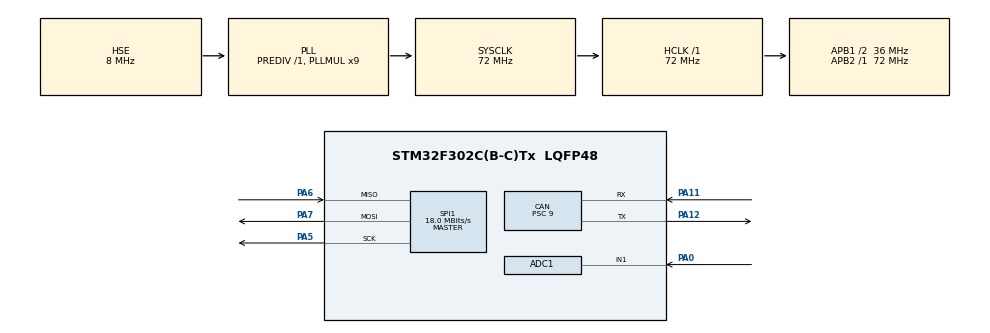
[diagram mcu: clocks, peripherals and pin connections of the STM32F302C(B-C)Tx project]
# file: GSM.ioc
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ADC1.Channel-0\#ChannelRegularConversion=ADC_CHANNEL_1
ADC1.NbrOfConversionFlag=1
ADC1.Offset-0\#ChannelRegularConversion=0
ADC1.OffsetNumber-0\#ChannelRegularConversion=ADC_OFFSET_NONE
ADC1.Rank-0\#ChannelRegularConversion=1
ADC1.SamplingTime-0\#ChannelRegularConversion=ADC_SAMPLETIME_1CYCLE_5
ADC1.SubFamily=STM32F302xC
ADC1.master=1
CAN.ABOM=ENABLE
CAN.BS1=CAN_BS1_6TQ
CAN.CalculateBaudRate=500000
CAN.CalculateTimeBit=2000
CAN.CalculateTimeQuantum=250.0
CAN.NART=ENABLE
CAN.Prescaler=9
CAN.RFLM=ENABLE
CAN.SJW=CAN_SJW_4TQ
FREERTOS.INCLUDE_uxTaskGetStackHighWaterMark=1
FREERTOS.INCLUDE_vTaskDelayUntil=1
FREERTOS.MEMORY_ALLOCATION=1
FREERTOS.Tasks01=Task100Hz,24,512,RunTask100Hz,Default,NULL,Static,Task100HzBuffer,Task100HzControlBlock;Task1Hz,24,512,RunTask1Hz,Default,NULL,Static,Task1HzBuffer,Task1HzControlBlock;Task1kHz,8,512,RunTask1kHz,Default,NULL,Static,Task1kHzBuffer,Task1kHzControlBlock;TaskCanRx,24,512,RunTaskCanRx,Default,NULL,Static,TaskCanRxBuffer,TaskCanRxControlBlock;TaskCanTx,24,512,RunTaskCanTx,Default,NULL,Static,TaskCanTxBuffer,TaskCanTxControlBlock
FREERTOS.configCHECK_FOR_STACK_OVERFLOW=2
FREERTOS.configUSE_NEWLIB_REENTRANT=1
FREERTOS.configUSE_TICK_HOOK=1
FREERTOS.configUSE_TRACE_FACILITY=1
IWDG.Reload=LSI_FREQUENCY / IWDG_PRESCALER / IWDG_RESET_FREQUENCY
IWDG.Window=IWDG_WINDOW_DISABLE_VALUE
Mcu.Family=STM32F3
Mcu.Name=STM32F302C(B-C)Tx
Mcu.Package=LQFP48
Mcu.UserConstants=IWDG_WINDOW_DISABLE_VALUE,4095;IWDG_PRESCALER,4;IWDG_RESET_FREQUENCY,5;LSI_FREQUENCY,40000;TASK_STACK_SIZE,512
NVIC.CAN_RX1_IRQn=true\:5\:0\:false\:false\:true\:true\:true\:true\:true
NVIC.PriorityGroup=NVIC_PRIORITYGROUP_4
NVIC.TIM1_UP_TIM16_IRQn=true\:0\:0\:false\:false\:true\:false\:false\:true\:true
NVIC.TimeBase=TIM1_UP_TIM16_IRQn
NVIC.TimeBaseIP=TIM1
NVIC.USB_HP_CAN_TX_IRQn=true\:5\:0\:false\:false\:true\:true\:true\:true\:true
NVIC.USB_LP_CAN_RX0_IRQn=true\:5\:0\:false\:false\:true\:true\:true\:true\:true
PA0.Mode=IN1-Single-Ended
PA0.Signal=ADC1_IN1
PA11.Mode=CAN_Activate
PA11.Signal=CAN_RX
PA12.Mode=CAN_Activate
PA12.Signal=CAN_TX
PA13.Mode=Trace_Asynchronous_SW
PA13.Signal=SYS_JTMS-SWDIO
PA14.Mode=Trace_Asynchronous_SW
PA14.Signal=SYS_JTCK-SWCLK
PA5.Mode=Full_Duplex_Master
PA5.Signal=SPI1_SCK
PA6.Mode=Full_Duplex_Master
PA6.Signal=SPI1_MISO
PA7.Mode=Full_Duplex_Master
PA7.Signal=SPI1_MOSI
PB3.Mode=Trace_Asynchronous_SW
PB3.Signal=SYS_JTDO-TRACESWO
PF0-OSC_IN.Mode=HSE-External-Oscillator
PF0-OSC_IN.Signal=RCC_OSC_IN
PF1-OSC_OUT.Mode=HSE-External-Oscillator
PF1-OSC_OUT.Signal=RCC_OSC_OUT
ProjectManager.HeapSize=0x0
ProjectManager.StackSize=0x400
ProjectManager.TargetToolchain=STM32CubeIDE
RCC.AHBFreq_Value=72000000
RCC.APB1CLKDivider=RCC_HCLK_DIV2
RCC.APB1Freq_Value=36000000
RCC.APB1TimFreq_Value=72000000
RCC.APB2Freq_Value=72000000
RCC.APB2TimFreq_Value=72000000
RCC.CortexFreq_Value=72000000
RCC.HCLKFreq_Value=72000000
RCC.HSE_VALUE=8000000
RCC.HSI_VALUE=8000000
RCC.LSE_VALUE=32768
RCC.PLLMUL=RCC_PLL_MUL9
RCC.PLLSourceVirtual=RCC_PLLSOURCE_HSE
RCC.SYSCLKFreq_VALUE=72000000
RCC.SYSCLKSourceVirtual=RCC_SYSCLKSOURCE_PLLCLK
RCC.USBFreq_Value=72000000
SPI1.BaudRatePrescaler=SPI_BAUDRATEPRESCALER_4
SPI1.CalculateBaudRate=18.0 MBits/s
SPI1.Direction=SPI_DIRECTION_2LINES
SPI1.Mode=SPI_MODE_MASTER
SPI1.VirtualType=VM_MASTER
VP_FREERTOS_VS_CMSIS_V2.Mode=CMSIS_V2
VP_IWDG_VS_IWDG.Mode=IWDG_Activate
VP_SYS_VS_tim1.Mode=TIM1
board=custom

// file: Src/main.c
/* USER CODE BEGIN Header */
/**
 ******************************************************************************
 * @file           : main.c
 * @brief          : Main program body
 ******************************************************************************
 * @attention
 *
 * <h2><center>&copy; Copyright (c) 2023 STMicroelectronics.
 * All rights reserved.</center></h2>
 *
 * This software component is licensed by ST under Ultimate Liberty license
 * SLA0044, the "License"; You may not use this file except in compliance with
 * the License. You may obtain a copy of the License at:
 *                             www.st.com/SLA0044
 *
 ******************************************************************************
 */
/* USER CODE END Header */
#include "main.h"
#include "cmsis_os.h"

typedef StaticTask_t osStaticThreadDef_t;

ADC_HandleTypeDef hadc1;

CAN_HandleTypeDef hcan;

IWDG_HandleTypeDef hiwdg;

SPI_HandleTypeDef hspi1;

/* Definitions for Task100Hz */
osThreadId_t         Task100HzHandle;
uint32_t             Task100HzBuffer[512];
osStaticThreadDef_t  Task100HzControlBlock;
const osThreadAttr_t Task100Hz_attributes = {
    .name       = "Task100Hz",
    .cb_mem     = &Task100HzControlBlock,
    .cb_size    = sizeof(Task100HzControlBlock),
    .stack_mem  = &Task100HzBuffer[0],
    .stack_size = sizeof(Task100HzBuffer),
    .priority   = (osPriority_t)osPriorityNormal,
};
/* Definitions for Task1Hz */
osThreadId_t         Task1HzHandle;
uint32_t             Task1HzBuffer[512];
osStaticThreadDef_t  Task1HzControlBlock;
const osThreadAttr_t Task1Hz_attributes = {
    .name       = "Task1Hz",
    .cb_mem     = &Task1HzControlBlock,
    .cb_size    = sizeof(Task1HzControlBlock),
    .stack_mem  = &Task1HzBuffer[0],
    .stack_size = sizeof(Task1HzBuffer),
    .priority   = (osPriority_t)osPriorityNormal,
};
/* Definitions for Task1kHz */
osThreadId_t         Task1kHzHandle;
uint32_t             Task1kHzBuffer[512];
osStaticThreadDef_t  Task1kHzControlBlock;
const osThreadAttr_t Task1kHz_attributes = {
    .name       = "Task1kHz",
    .cb_mem     = &Task1kHzControlBlock,
    .cb_size    = sizeof(Task1kHzControlBlock),
    .stack_mem  = &Task1kHzBuffer[0],
    .stack_size = sizeof(Task1kHzBuffer),
    .priority   = (osPriority_t)osPriorityLow,
};
/* Definitions for TaskCanRx */
osThreadId_t         TaskCanRxHandle;
uint32_t             TaskCanRxBuffer[512];
osStaticThreadDef_t  TaskCanRxControlBlock;
const osThreadAttr_t TaskCanRx_attributes = {
    .name       = "TaskCanRx",
    .cb_mem     = &TaskCanRxControlBlock,
    .cb_size    = sizeof(TaskCanRxControlBlock),
    .stack_mem  = &TaskCanRxBuffer[0],
    .stack_size = sizeof(TaskCanRxBuffer),
    .priority   = (osPriority_t)osPriorityNormal,
};
/* Definitions for TaskCanTx */
osThreadId_t         TaskCanTxHandle;
uint32_t             TaskCanTxBuffer[512];
osStaticThreadDef_t  TaskCanTxControlBlock;
const osThreadAttr_t TaskCanTx_attributes = {
    .name       = "TaskCanTx",
    .cb_mem     = &TaskCanTxControlBlock,
    .cb_size    = sizeof(TaskCanTxControlBlock),
    .stack_mem  = &TaskCanTxBuffer[0],
    .stack_size = sizeof(TaskCanTxBuffer),
    .priority   = (osPriority_t)osPriorityNormal,
};

void        SystemClock_Config(void);
static void MX_GPIO_Init(void);
static void MX_CAN_Init(void);
static void MX_ADC1_Init(void);
static void MX_SPI1_Init(void);
static void MX_IWDG_Init(void);
void        RunTask100Hz(void *argument);
void        RunTask1Hz(void *argument);
void        RunTask1kHz(void *argument);
void        RunTaskCanRx(void *argument);
void        RunTaskCanTx(void *argument);

int main(void)
{

    /* MCU Configuration--------------------------------------------------------*/

    /* Reset of all peripherals, Initializes the Flash interface and the Systick. */
    HAL_Init();

    /* Configure the system clock */
    SystemClock_Config();

    /* Initialize all configured peripherals */
    MX_GPIO_Init();
    MX_CAN_Init();
    MX_ADC1_Init();
    MX_SPI1_Init();
    MX_IWDG_Init();

    /* Init scheduler */
    osKernelInitialize();

    /* Create the thread(s) */
    /* creation of Task100Hz */
    Task100HzHandle = osThreadNew(RunTask100Hz, NULL, &Task100Hz_attributes);

    /* creation of Task1Hz */
    Task1HzHandle = osThreadNew(RunTask1Hz, NULL, &Task1Hz_attributes);

    /* creation of Task1kHz */
    Task1kHzHandle = osThreadNew(RunTask1kHz, NULL, &Task1kHz_attributes);

    /* creation of TaskCanRx */
    TaskCanRxHandle = osThreadNew(RunTaskCanRx, NULL, &TaskCanRx_attributes);

    /* creation of TaskCanTx */
    TaskCanTxHandle = osThreadNew(RunTaskCanTx, NULL, &TaskCanTx_attributes);

    /* Start scheduler */
    osKernelStart();

    /* We should never get here as control is now taken by the scheduler */
    /* Infinite loop */
    while (1)
    {

    }
}

void SystemClock_Config(void)
{
    RCC_OscInitTypeDef       RCC_OscInitStruct = { 0 };
    RCC_ClkInitTypeDef       RCC_ClkInitStruct = { 0 };
    RCC_PeriphCLKInitTypeDef PeriphClkInit     = { 0 };

    /** Initializes the RCC Oscillators according to the specified parameters
     * in the RCC_OscInitTypeDef structure.
     */
    RCC_OscInitStruct.OscillatorType = RCC_OSCILLATORTYPE_LSI | RCC_OSCILLATORTYPE_HSE;
    RCC_OscInitStruct.HSEState       = RCC_HSE_ON;
    RCC_OscInitStruct.HSEPredivValue = RCC_HSE_PREDIV_DIV1;
    RCC_OscInitStruct.HSIState       = RCC_HSI_ON;
    RCC_OscInitStruct.LSIState       = RCC_LSI_ON;
    RCC_OscInitStruct.PLL.PLLState   = RCC_PLL_ON;
    RCC_OscInitStruct.PLL.PLLSource  = RCC_PLLSOURCE_HSE;
    RCC_OscInitStruct.PLL.PLLMUL     = RCC_PLL_MUL9;
    if (HAL_RCC_OscConfig(&RCC_OscInitStruct) != HAL_OK)
    {
        Error_Handler();
    }

    /** Initializes the CPU, AHB and APB buses clocks
     */
    RCC_ClkInitStruct.ClockType = RCC_CLOCKTYPE_HCLK | RCC_CLOCKTYPE_SYSCLK | RCC_CLOCKTYPE_PCLK1 | RCC_CLOCKTYPE_PCLK2;
    RCC_ClkInitStruct.SYSCLKSource   = RCC_SYSCLKSOURCE_PLLCLK;
    RCC_ClkInitStruct.AHBCLKDivider  = RCC_SYSCLK_DIV1;
    RCC_ClkInitStruct.APB1CLKDivider = RCC_HCLK_DIV2;
    RCC_ClkInitStruct.APB2CLKDivider = RCC_HCLK_DIV1;

    if (HAL_RCC_ClockConfig(&RCC_ClkInitStruct, FLASH_LATENCY_2) != HAL_OK)
    {
        Error_Handler();
    }
    PeriphClkInit.PeriphClockSelection = RCC_PERIPHCLK_ADC12;
    PeriphClkInit.Adc12ClockSelection  = RCC_ADC12PLLCLK_DIV1;
    if (HAL_RCCEx_PeriphCLKConfig(&PeriphClkInit) != HAL_OK)
    {
        Error_Handler();
    }
}

static void MX_ADC1_Init(void)
{

    ADC_MultiModeTypeDef   multimode = { 0 };
    ADC_ChannelConfTypeDef sConfig   = { 0 };

    /** Common config
     */
    hadc1.Instance                   = ADC1;
    hadc1.Init.ClockPrescaler        = ADC_CLOCK_ASYNC_DIV1;
    hadc1.Init.Resolution            = ADC_RESOLUTION_12B;
    hadc1.Init.ScanConvMode          = ADC_SCAN_DISABLE;
    hadc1.Init.ContinuousConvMode    = DISABLE;
    hadc1.Init.DiscontinuousConvMode = DISABLE;
    hadc1.Init.ExternalTrigConvEdge  = ADC_EXTERNALTRIGCONVEDGE_NONE;
    hadc1.Init.ExternalTrigConv      = ADC_SOFTWARE_START;
    hadc1.Init.DataAlign             = ADC_DATAALIGN_RIGHT;
    hadc1.Init.NbrOfConversion       = 1;
    hadc1.Init.DMAContinuousRequests = DISABLE;
    hadc1.Init.EOCSelection          = ADC_EOC_SINGLE_CONV;
    hadc1.Init.LowPowerAutoWait      = DISABLE;
    hadc1.Init.Overrun               = ADC_OVR_DATA_OVERWRITTEN;
    if (HAL_ADC_Init(&hadc1) != HAL_OK)
    {
        Error_Handler();
    }

    /** Configure the ADC multi-mode
     */
    multimode.Mode = ADC_MODE_INDEPENDENT;
    if (HAL_ADCEx_MultiModeConfigChannel(&hadc1, &multimode) != HAL_OK)
    {
        Error_Handler();
    }

    /** Configure Regular Channel
     */
    sConfig.Channel      = ADC_CHANNEL_1;
    sConfig.Rank         = ADC_REGULAR_RANK_1;
    sConfig.SingleDiff   = ADC_SINGLE_ENDED;
    sConfig.SamplingTime = ADC_SAMPLETIME_1CYCLE_5;
    sConfig.OffsetNumber = ADC_OFFSET_NONE;
    sConfig.Offset       = 0;
    if (HAL_ADC_ConfigChannel(&hadc1, &sConfig) != HAL_OK)
    {
        Error_Handler();
    }
}

static void MX_CAN_Init(void)
{

    hcan.Instance                  = CAN;
    hcan.Init.Prescaler            = 9;
    hcan.Init.Mode                 = CAN_MODE_NORMAL;
    hcan.Init.SyncJumpWidth        = CAN_SJW_4TQ;
    hcan.Init.TimeSeg1             = CAN_BS1_6TQ;
    hcan.Init.TimeSeg2             = CAN_BS2_1TQ;
    hcan.Init.TimeTriggeredMode    = DISABLE;
    hcan.Init.AutoBusOff           = ENABLE;
    hcan.Init.AutoWakeUp           = DISABLE;
    hcan.Init.AutoRetransmission   = ENABLE;
    hcan.Init.ReceiveFifoLocked    = ENABLE;
    hcan.Init.TransmitFifoPriority = DISABLE;
    if (HAL_CAN_Init(&hcan) != HAL_OK)
    {
        Error_Handler();
    }
}

static void MX_IWDG_Init(void)
{

    hiwdg.Instance       = IWDG;
    hiwdg.Init.Prescaler = IWDG_PRESCALER_4;
    hiwdg.Init.Window    = IWDG_WINDOW_DISABLE_VALUE;
    hiwdg.Init.Reload    = LSI_FREQUENCY / IWDG_PRESCALER / IWDG_RESET_FREQUENCY;
    if (HAL_IWDG_Init(&hiwdg) != HAL_OK)
    {
        Error_Handler();
    }
}

static void MX_SPI1_Init(void)
{

    /* SPI1 parameter configuration*/
    hspi1.Instance               = SPI1;
    hspi1.Init.Mode              = SPI_MODE_MASTER;
    hspi1.Init.Direction         = SPI_DIRECTION_2LINES;
    hspi1.Init.DataSize          = SPI_DATASIZE_4BIT;
    hspi1.Init.CLKPolarity       = SPI_POLARITY_LOW;
    hspi1.Init.CLKPhase          = SPI_PHASE_1EDGE;
    hspi1.Init.NSS               = SPI_NSS_SOFT;
    hspi1.Init.BaudRatePrescaler = SPI_BAUDRATEPRESCALER_4;
    hspi1.Init.FirstBit          = SPI_FIRSTBIT_MSB;
    hspi1.Init.TIMode            = SPI_TIMODE_DISABLE;
    hspi1.Init.CRCCalculation    = SPI_CRCCALCULATION_DISABLE;
    hspi1.Init.CRCPolynomial     = 7;
    hspi1.Init.CRCLength         = SPI_CRC_LENGTH_DATASIZE;
    hspi1.Init.NSSPMode          = SPI_NSS_PULSE_ENABLE;
    if (HAL_SPI_Init(&hspi1) != HAL_OK)
    {
        Error_Handler();
    }
}

static void MX_GPIO_Init(void)
{
    GPIO_InitTypeDef GPIO_InitStruct = { 0 };

    /* GPIO Ports Clock Enable */
    __HAL_RCC_GPIOC_CLK_ENABLE();
    __HAL_RCC_GPIOF_CLK_ENABLE();
    __HAL_RCC_GPIOA_CLK_ENABLE();
    __HAL_RCC_GPIOB_CLK_ENABLE();

    /*Configure GPIO pins : PC13 PC14 PC15 */
    GPIO_InitStruct.Pin  = GPIO_PIN_13 | GPIO_PIN_14 | GPIO_PIN_15;
    GPIO_InitStruct.Mode = GPIO_MODE_ANALOG;
    GPIO_InitStruct.Pull = GPIO_NOPULL;
    HAL_GPIO_Init(GPIOC, &GPIO_InitStruct);

    /*Configure GPIO pins : PA1 PA2 PA3 PA4
                             PA8 PA9 PA10 PA15 */
    GPIO_InitStruct.Pin =
        GPIO_PIN_1 | GPIO_PIN_2 | GPIO_PIN_3 | GPIO_PIN_4 | GPIO_PIN_8 | GPIO_PIN_9 | GPIO_PIN_10 | GPIO_PIN_15;
    GPIO_InitStruct.Mode = GPIO_MODE_ANALOG;
    GPIO_InitStruct.Pull = GPIO_NOPULL;
    HAL_GPIO_Init(GPIOA, &GPIO_InitStruct);

    /*Configure GPIO pins : PB0 PB1 PB2 PB10
                             PB11 PB12 PB13 PB14
                             PB15 PB4 PB5 PB6
                             PB7 PB8 PB9 */
    GPIO_InitStruct.Pin = GPIO_PIN_0 | GPIO_PIN_1 | GPIO_PIN_2 | GPIO_PIN_10 | GPIO_PIN_11 | GPIO_PIN_12 | GPIO_PIN_13 |
                          GPIO_PIN_14 | GPIO_PIN_15 | GPIO_PIN_4 | GPIO_PIN_5 | GPIO_PIN_6 | GPIO_PIN_7 | GPIO_PIN_8 |
                          GPIO_PIN_9;
    GPIO_InitStruct.Mode = GPIO_MODE_ANALOG;
    GPIO_InitStruct.Pull = GPIO_NOPULL;
    HAL_GPIO_Init(GPIOB, &GPIO_InitStruct);

}

void RunTask100Hz(void *argument)
{
    for (;;)
    {
        osDelay(1);
    }
}

void RunTask1Hz(void *argument)
{
    for (;;)
    {
        osDelay(1);
    }
}

void RunTask1kHz(void *argument)
{
    for (;;)
    {
        osDelay(1);
    }
}

void RunTaskCanRx(void *argument)
{
    for (;;)
    {
        osDelay(1);
    }
}

void RunTaskCanTx(void *argument)
{
    for (;;)
    {
        osDelay(1);
    }
}

void HAL_TIM_PeriodElapsedCallback(TIM_HandleTypeDef *htim)
{
    if (htim->Instance == TIM1)
    {
        HAL_IncTick();
    }
}

void Error_Handler(void)
{
}

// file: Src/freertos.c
/* USER CODE BEGIN Header */
/**
 ******************************************************************************
 * File Name          : freertos.c
 * Description        : Code for freertos applications
 ******************************************************************************
 * @attention
 *
 * <h2><center>&copy; Copyright (c) 2022 STMicroelectronics.
 * All rights reserved.</center></h2>
 *
 * This software component is licensed by ST under Ultimate Liberty license
 * SLA0044, the "License"; You may not use this file except in compliance with
 * the License. You may obtain a copy of the License at:
 *                             www.st.com/SLA0044
 *
 ******************************************************************************
 */
/* USER CODE END Header */

#include "FreeRTOS.h"
#include "task.h"
#include "main.h"

/* Hook prototypes */
void vApplicationTickHook(void);
void vApplicationStackOverflowHook(xTaskHandle xTask, signed char *pcTaskName);

/* USER CODE BEGIN 3 */
__weak void vApplicationTickHook(void)
{
    /* This function will be called by each tick interrupt if
    configUSE_TICK_HOOK is set to 1 in FreeRTOSConfig.h. User code can be
    added here, but the tick hook is called from an interrupt context, so
    code must not attempt to block, and only the interrupt safe FreeRTOS API
    functions can be used (those that end in FromISR()). */
}
/* USER CODE END 3 */

/* USER CODE BEGIN 4 */
__weak void vApplicationStackOverflowHook(xTaskHandle xTask, signed char *pcTaskName)
{
    /* Run time stack overflow checking is performed if
    configCHECK_FOR_STACK_OVERFLOW is defined to 1 or 2. This hook function is
    called if a stack overflow is detected. */
}
/* USER CODE END 4 */
